# GICSS0_GIC register map
Vendor: Texas Instruments
Peripheral module from a debugger description file (folder am62A).
Registers are 32-bit, access not given, no defined reset value unless marked. A register's access mark holds for its fields unless they carry their own. Offsets are as the file gives them; lines under a group give offsets from that group; [hi:lo] are bit positions; {n}, {i} and the like mark numbered series; 'fields as' and 'values as' point back to an identical list; <NAME> marks a mode.

## GICSS0_GIC
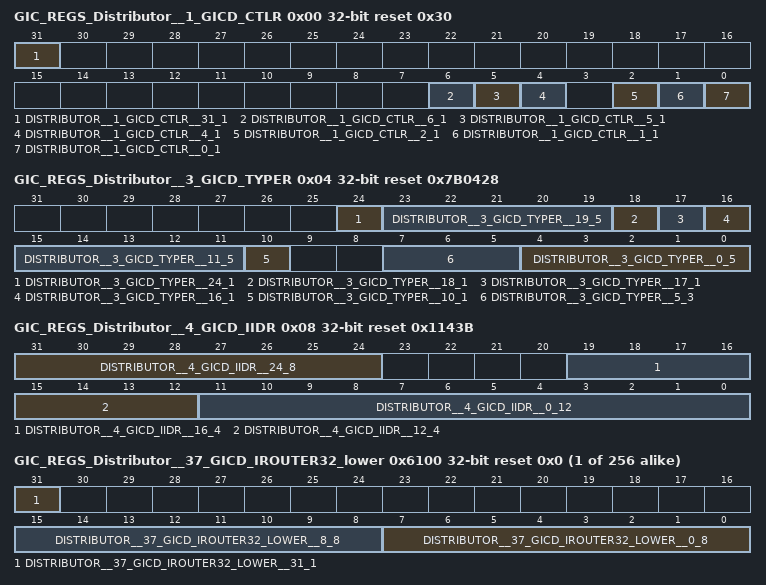
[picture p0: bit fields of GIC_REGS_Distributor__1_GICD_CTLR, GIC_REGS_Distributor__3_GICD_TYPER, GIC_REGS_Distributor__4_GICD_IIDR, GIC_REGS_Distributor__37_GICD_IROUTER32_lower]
0x00 GIC_REGS_Distributor__1_GICD_CTLR rw reset 0x30 — GICD_CTLR
  [31] DISTRIBUTOR__1_GICD_CTLR__31_1 — Register Write Pending
  [6] DISTRIBUTOR__1_GICD_CTLR__6_1 — S: DS
  [5] DISTRIBUTOR__1_GICD_CTLR__5_1 — S: ARE_NS
  [4] DISTRIBUTOR__1_GICD_CTLR__4_1 — NS: ARE_NS S: ARE_S
  [2] DISTRIBUTOR__1_GICD_CTLR__2_1 — S: EnableGrp1_S
  [1] DISTRIBUTOR__1_GICD_CTLR__1_1 — NS: EnableGrp1A S: EnableGrp1_NS
  [0] DISTRIBUTOR__1_GICD_CTLR__0_1 — NS: EnableGrp1 S: EnableGrp0
0x04 GIC_REGS_Distributor__3_GICD_TYPER rw reset 0x7B0428 — GICD_TYPER
  [24] DISTRIBUTOR__3_GICD_TYPER__24_1 — A3V
  [23:19] DISTRIBUTOR__3_GICD_TYPER__19_5 — IDbits
  [18] DISTRIBUTOR__3_GICD_TYPER__18_1 — DVIS
  [17] DISTRIBUTOR__3_GICD_TYPER__17_1 — LPIS
  [16] DISTRIBUTOR__3_GICD_TYPER__16_1 — MBIS
  [15:11] DISTRIBUTOR__3_GICD_TYPER__11_5 — LSPI
  [10] DISTRIBUTOR__3_GICD_TYPER__10_1 — SecurityExtn
  [7:5] DISTRIBUTOR__3_GICD_TYPER__5_3 — CPUNumber
  [4:0] DISTRIBUTOR__3_GICD_TYPER__0_5 — ITLinesNumber
0x08 GIC_REGS_Distributor__4_GICD_IIDR rw reset 0x1143B — GICD_IIDR
  [31:24] DISTRIBUTOR__4_GICD_IIDR__24_8 — ProductID
  [19:16] DISTRIBUTOR__4_GICD_IIDR__16_4 — Variant
  [15:12] DISTRIBUTOR__4_GICD_IIDR__12_4 — Revision
  [11:0] DISTRIBUTOR__4_GICD_IIDR__0_12 — Implementer
0x40 GIC_REGS_Distributor__5_GICD_SETSPI_NSR rw reset 0x0 — GICD_SETSPI_NSR
  [9:0] DISTRIBUTOR__5_GICD_SETSPI_NSR__0_10 — SPI ID
0x48 GIC_REGS_Distributor__6_GICD_CLRSPI_NSR rw reset 0x0 — GICD_CLRSPI_NSR
  [9:0] DISTRIBUTOR__6_GICD_CLRSPI_NSR__0_10 — SPI ID
0x50 GIC_REGS_Distributor__7_GICD_SETSPI_SR rw reset 0x0 — GICD_SETSPI_SR
  [9:0] DISTRIBUTOR__7_GICD_SETSPI_SR__0_10 — SPI ID
0x58 GIC_REGS_Distributor__8_GICD_CLRSPI_SR rw reset 0x0 — GICD_CLRSPI_SR
  [9:0] DISTRIBUTOR__8_GICD_CLRSPI_SR__0_10 — SPI ID
0x80 GIC_REGS_Distributor__9_GICD_IGROUPR0 — GICD_IGROUPR0
{0x80+4i} GIC_REGS_Distributor__10_GICD_IGROUPR{i} (i=1..8) — GICD_IGROUPR{i}
{0x100+4i} GIC_REGS_Distributor__12_GICD_ISENABLER{i} (i=1..8) — GICD_ISENABLER{i}
{0x180+4i} GIC_REGS_Distributor__14_GICD_ICENABLER{i} (i=1..8) — GICD_ICENABLER{i}
{0x200+4i} GIC_REGS_Distributor__16_GICD_ISPENDR{i} (i=1..8) — GICD_ISPENDR{i}
{0x280+4i} GIC_REGS_Distributor__18_GICD_ICPENDR{i} (i=1..8) — GICD_ICPENDR{i}
{0x300+4i} GIC_REGS_Distributor__20_GICD_ISACTIVER{i} (i=1..8) — GICD_ISACTIVER{i}
{0x380+4i} GIC_REGS_Distributor__22_GICD_ICACTIVER{i} (i=1..8) — GICD_ICACTIVER{i}
{0x400+4i} GIC_REGS_Distributor__24_GICD_IPRIORITYR{i} (i=8..71) — GICD_IPRIORITYR{i}
{0x800+4i} GIC_REGS_Distributor__26_GICD_ITARGETSR{i} (i=8..71) — GICD_ITARGETSR{i}
{0xC00+4i} GIC_REGS_Distributor__29_GICD_ICFGR{i} (i=2..17) — GICD_ICFGR{i}
0xD00 GIC_REGS_Distributor__30_GICD_IGRPMODR0 — GICD_IGRPMODR0
{0xD00+4i} GIC_REGS_Distributor__31_GICD_IGRPMODR{i} (i=1..8) — GICD_IGRPMODR{i}
0xE00 GIC_REGS_Distributor__32_GICD_NSACR0 — GICD_NSACR0
0xE04 GIC_REGS_Distributor__32_GICD_NSACR1 — GICD_NSACR1
{0xE00+4i} GIC_REGS_Distributor__33_GICD_NSACR{i} (i=2..17) — GICD_NSACR{i}
{0x6000+8i} GIC_REGS_Distributor__37_GICD_IROUTER{i}_lower rw reset 0x0 (i=32..287) — GICD_IROUTER{i}_lower
  [31] DISTRIBUTOR__37_GICD_IROUTER{i}_LOWER__31_1 — IRM
  [15:8] DISTRIBUTOR__37_GICD_IROUTER{i}_LOWER__8_8 — A1
  [7:0] DISTRIBUTOR__37_GICD_IROUTER{i}_LOWER__0_8 — A0
{0x6004+8i} GIC_REGS_Distributor__37_GICD_IROUTER{i}_upper (i=32..287) — GICD_IROUTER{i}_upper
0xC000 GIC_REGS_Distributor__38_GICD_ESTATUSR rw reset 0x0 — GICD_ESTATUSR
  [31] DISTRIBUTOR__38_GICD_ESTATUSR__31_1 — SWRP
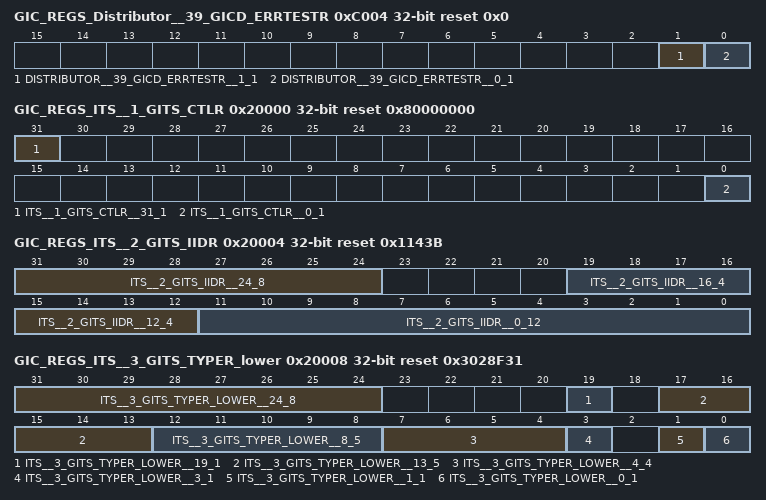
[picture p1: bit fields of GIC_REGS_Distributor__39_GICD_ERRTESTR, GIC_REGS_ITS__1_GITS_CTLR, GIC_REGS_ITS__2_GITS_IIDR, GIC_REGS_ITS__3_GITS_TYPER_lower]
0xC004 GIC_REGS_Distributor__39_GICD_ERRTESTR rw reset 0x0 — GICD_ERRTESTR
  [1] DISTRIBUTOR__39_GICD_ERRTESTR__1_1 — AXIM_err
  [0] DISTRIBUTOR__39_GICD_ERRTESTR__0_1 — ECC_fatal
{0xC084+4i} GIC_REGS_Distributor__40_GICD_SPISR{i} (i=0..7) — GICD_SPISR{i}
{0xFF2C+4i} GIC_REGS_Distributor__{i}_GICD_PIDR{i-37} (i=41..44) — GICD_PIDR{i-37}
{0xFF2C+4i} GIC_REGS_Distributor__{i}_GICD_PIDR{i-45} (i=45..48) — GICD_PIDR{i-45}
{0xFF2C+4i} GIC_REGS_Distributor__{i}_GICD_CIDR{i-49} (i=49..52) — GICD_CIDR{i-49}
0x10040 GIC_REGS_Message_based_SPIs__1_GICD_SETSPI_NSR rw reset 0x0 — GICD_SETSPI_NSR
  [9:0] MESSAGE_BASED_SPIS__1_GICD_SETSPI_NSR__0_10 — SPI ID
0x10048 GIC_REGS_Message_based_SPIs__2_GICD_CLRSPI_NSR rw reset 0x0 — GICD_CLRSPI_NSR
  [9:0] MESSAGE_BASED_SPIS__2_GICD_CLRSPI_NSR__0_10 — SPI ID
0x10050 GIC_REGS_Message_based_SPIs__3_GICD_SETSPI_SR rw reset 0x0 — GICD_SETSPI_SR
  [9:0] MESSAGE_BASED_SPIS__3_GICD_SETSPI_SR__0_10 — SPI ID
0x10058 GIC_REGS_Message_based_SPIs__4_GICD_CLRSPI_SR rw reset 0x0 — GICD_CLRSPI_SR
  [9:0] MESSAGE_BASED_SPIS__4_GICD_CLRSPI_SR__0_10 — SPI ID
0x20000 GIC_REGS_ITS__1_GITS_CTLR rw reset 0x80000000 — GITS_CTLR
  [31] ITS__1_GITS_CTLR__31_1 — Quiescent
  [0] ITS__1_GITS_CTLR__0_1 — Enabled
0x20004 GIC_REGS_ITS__2_GITS_IIDR rw reset 0x1143B — GITS_IIDR
  [31:24] ITS__2_GITS_IIDR__24_8 — ProductID
  [19:16] ITS__2_GITS_IIDR__16_4 — Variant
  [15:12] ITS__2_GITS_IIDR__12_4 — Revision
  [11:0] ITS__2_GITS_IIDR__0_12 — Implementer
0x20008 GIC_REGS_ITS__3_GITS_TYPER_lower rw reset 0x3028F31 — GITS_TYPER_lower
  [31:24] ITS__3_GITS_TYPER_LOWER__24_8 — HCC
  [19] ITS__3_GITS_TYPER_LOWER__19_1 — PTA
  [17:13] ITS__3_GITS_TYPER_LOWER__13_5 — Devbits
  [12:8] ITS__3_GITS_TYPER_LOWER__8_5 — IDbits
  [7:4] ITS__3_GITS_TYPER_LOWER__4_4 — ITT Entry Size
  [3] ITS__3_GITS_TYPER_LOWER__3_1 — Distributed
  [1] ITS__3_GITS_TYPER_LOWER__1_1 — VLPIS
  [0] ITS__3_GITS_TYPER_LOWER__0_1 — PLPIS
0x2000C GIC_REGS_ITS__4_GITS_TYPER_upper — GITS_TYPER_upper
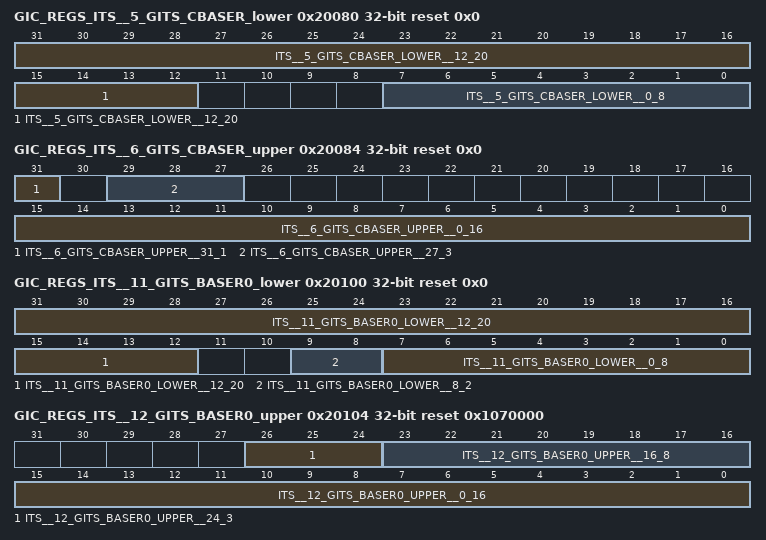
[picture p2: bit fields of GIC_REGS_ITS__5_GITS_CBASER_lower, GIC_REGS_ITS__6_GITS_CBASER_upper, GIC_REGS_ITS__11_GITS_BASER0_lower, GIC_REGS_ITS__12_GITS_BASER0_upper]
0x20080 GIC_REGS_ITS__5_GITS_CBASER_lower rw reset 0x0 — GITS_CBASER_lower
  [31:12] ITS__5_GITS_CBASER_LOWER__12_20 — Physical Address [31:12]
  [7:0] ITS__5_GITS_CBASER_LOWER__0_8 — Size
0x20084 GIC_REGS_ITS__6_GITS_CBASER_upper rw reset 0x0 — GITS_CBASER_upper
  [31] ITS__6_GITS_CBASER_UPPER__31_1 — Valid
  [29:27] ITS__6_GITS_CBASER_UPPER__27_3 — Cacheability
  [15:0] ITS__6_GITS_CBASER_UPPER__0_16 — Physical Address [47:32]
0x20088 GIC_REGS_ITS__7_GITS_CWRITER_lower rw reset 0x0 — GITS_CWRITER_lower
  [19:5] ITS__7_GITS_CWRITER_LOWER__5_15 — Offset
0x2008C GIC_REGS_ITS__8_GITS_CWRITER_upper — GITS_CWRITER_upper
0x20090 GIC_REGS_ITS__9_GITS_CREADR_lower rw reset 0x0 — GITS_CREADR_lower
  [19:5] ITS__9_GITS_CREADR_LOWER__5_15 — Offset
0x20094 GIC_REGS_ITS__10_GITS_CREADR_upper — GITS_CREADR_upper
0x20100 GIC_REGS_ITS__11_GITS_BASER0_lower rw reset 0x0 — GITS_BASER0_lower
  [31:12] ITS__11_GITS_BASER0_LOWER__12_20 — Physical Address [31:12]
  [9:8] ITS__11_GITS_BASER0_LOWER__8_2 — Page Size
  [7:0] ITS__11_GITS_BASER0_LOWER__0_8 — Size
0x20104 GIC_REGS_ITS__12_GITS_BASER0_upper rw reset 0x1070000 — GITS_BASER0_upper
  [26:24] ITS__12_GITS_BASER0_UPPER__24_3 — Type
  [23:16] ITS__12_GITS_BASER0_UPPER__16_8 — Entry Size
  [15:0] ITS__12_GITS_BASER0_UPPER__0_16 — Physical Address [47:32]
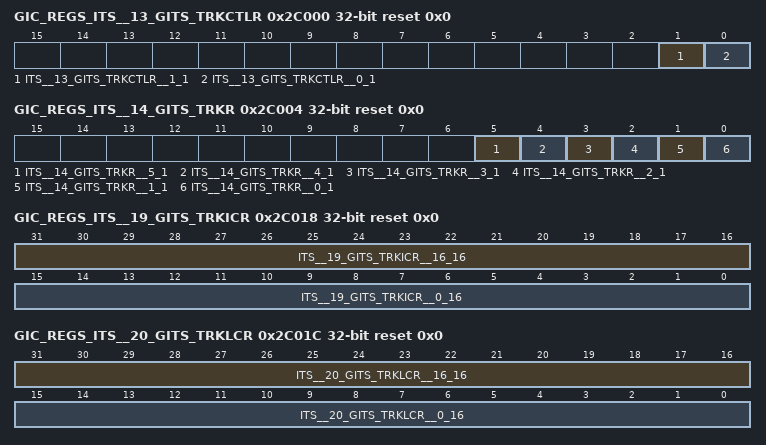
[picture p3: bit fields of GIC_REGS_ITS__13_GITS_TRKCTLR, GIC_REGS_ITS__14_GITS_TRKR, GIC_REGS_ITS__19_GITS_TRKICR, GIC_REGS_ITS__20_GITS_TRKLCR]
0x2C000 GIC_REGS_ITS__13_GITS_TRKCTLR rw reset 0x0 — GITS_TRKCTLR
  [1] ITS__13_GITS_TRKCTLR__1_1 — ITS track
  [0] ITS__13_GITS_TRKCTLR__0_1 — Cache count reset
0x2C004 GIC_REGS_ITS__14_GITS_TRKR rw reset 0x0 — GITS_TRKR
  [5] ITS__14_GITS_TRKR__5_1 — Translated ID out of range
  [4] ITS__14_GITS_TRKR__4_1 — Target CPU out of range
  [3] ITS__14_GITS_TRKR__3_1 — DID/ID not mapped
  [2] ITS__14_GITS_TRKR__2_1 — Input ID out of range
  [1] ITS__14_GITS_TRKR__1_1 — DID unmapped
  [0] ITS__14_GITS_TRKR__0_1 — DID out of range
0x2C008 GIC_REGS_ITS__15_GITS_TRKDIDR rw reset 0x0 — GITS_TRKDIDR
  [19:0] ITS__15_GITS_TRKDIDR__0_20 — DID
0x2C00C GIC_REGS_ITS__16_GITS_TRKPIDR rw reset 0x0 — GITS_TRKPIDR
  [15:0] ITS__16_GITS_TRKPIDR__0_16 — Translated ID
0x2C010 GIC_REGS_ITS__17_GITS_TRKVIDR rw reset 0x0 — GITS_TRKVIDR
  [15:0] ITS__17_GITS_TRKVIDR__0_16 — Input ID
0x2C014 GIC_REGS_ITS__18_GITS_TRKTGTR rw reset 0x0 — GITS_TRKTGTR
  [6:0] ITS__18_GITS_TRKTGTR__0_7 — Target CPU
0x2C018 GIC_REGS_ITS__19_GITS_TRKICR rw reset 0x0 — GITS_TRKICR
  [31:16] ITS__19_GITS_TRKICR__16_16 — ITE cache hits
  [15:0] ITS__19_GITS_TRKICR__0_16 — ITE cache misses
0x2C01C GIC_REGS_ITS__20_GITS_TRKLCR rw reset 0x0 — GITS_TRKLCR
  [31:16] ITS__20_GITS_TRKLCR__16_16 — LPI cache hits
  [15:0] ITS__20_GITS_TRKLCR__0_16 — LPI cache misses
{0x2FF7C+4i} GIC_REGS_ITS__{i}_GITS_PIDR{i-17} (i=21..24) — GITS_PIDR{i-17}
{0x2FF7C+4i} GIC_REGS_ITS__{i}_GITS_PIDR{i-25} (i=25..28) — GITS_PIDR{i-25}
{0x2FF7C+4i} GIC_REGS_ITS__{i}_GITS_CIDR{i-29} (i=29..32) — GITS_CIDR{i-29}
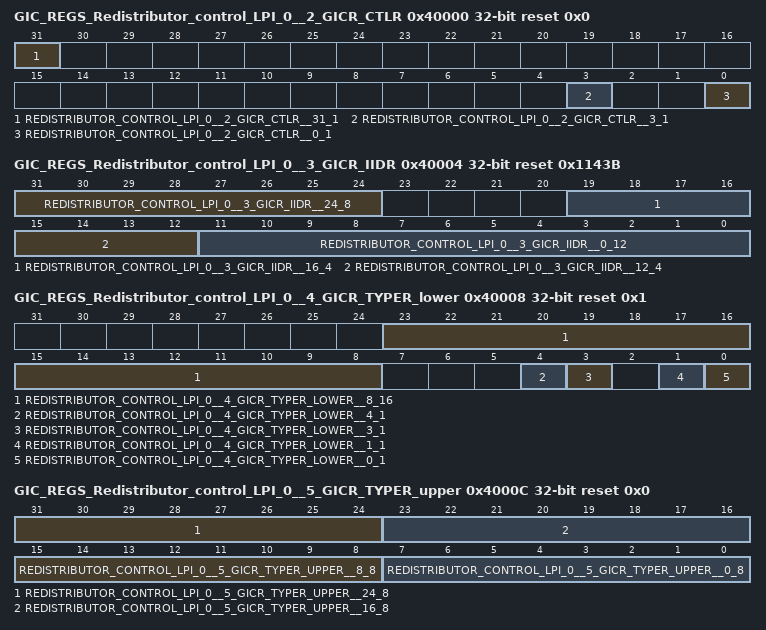
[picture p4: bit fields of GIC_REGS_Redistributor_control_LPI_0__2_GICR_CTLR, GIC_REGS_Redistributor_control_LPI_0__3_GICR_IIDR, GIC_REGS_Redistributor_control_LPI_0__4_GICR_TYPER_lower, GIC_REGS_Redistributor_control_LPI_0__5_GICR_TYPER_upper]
0x40000 GIC_REGS_Redistributor_control_LPI_0__2_GICR_CTLR rw reset 0x0 — GICR_CTLR
  [31] REDISTRIBUTOR_CONTROL_LPI_0__2_GICR_CTLR__31_1 — Upstream Write Pending
  [3] REDISTRIBUTOR_CONTROL_LPI_0__2_GICR_CTLR__3_1 — Register Write Pending
  [0] REDISTRIBUTOR_CONTROL_LPI_0__2_GICR_CTLR__0_1 — Enable LPIs
0x40004 GIC_REGS_Redistributor_control_LPI_0__3_GICR_IIDR rw reset 0x1143B — GICR_IIDR
  [31:24] REDISTRIBUTOR_CONTROL_LPI_0__3_GICR_IIDR__24_8 — ProductID
  [19:16] REDISTRIBUTOR_CONTROL_LPI_0__3_GICR_IIDR__16_4 — Variant
  [15:12] REDISTRIBUTOR_CONTROL_LPI_0__3_GICR_IIDR__12_4 — Revision
  [11:0] REDISTRIBUTOR_CONTROL_LPI_0__3_GICR_IIDR__0_12 — Implementer
0x40008 GIC_REGS_Redistributor_control_LPI_0__4_GICR_TYPER_lower rw reset 0x1 — GICR_TYPER_lower
  [23:8] REDISTRIBUTOR_CONTROL_LPI_0__4_GICR_TYPER_LOWER__8_16 — Processor Number
  [4] REDISTRIBUTOR_CONTROL_LPI_0__4_GICR_TYPER_LOWER__4_1 — Last
  [3] REDISTRIBUTOR_CONTROL_LPI_0__4_GICR_TYPER_LOWER__3_1 — Distributed
  [1] REDISTRIBUTOR_CONTROL_LPI_0__4_GICR_TYPER_LOWER__1_1 — VLPIS
  [0] REDISTRIBUTOR_CONTROL_LPI_0__4_GICR_TYPER_LOWER__0_1 — PLPIS
0x4000C GIC_REGS_Redistributor_control_LPI_0__5_GICR_TYPER_upper rw reset 0x0 — GICR_TYPER_upper
  [31:24] REDISTRIBUTOR_CONTROL_LPI_0__5_GICR_TYPER_UPPER__24_8 — A3
  [23:16] REDISTRIBUTOR_CONTROL_LPI_0__5_GICR_TYPER_UPPER__16_8 — A2
  [15:8] REDISTRIBUTOR_CONTROL_LPI_0__5_GICR_TYPER_UPPER__8_8 — A1
  [7:0] REDISTRIBUTOR_CONTROL_LPI_0__5_GICR_TYPER_UPPER__0_8 — A0
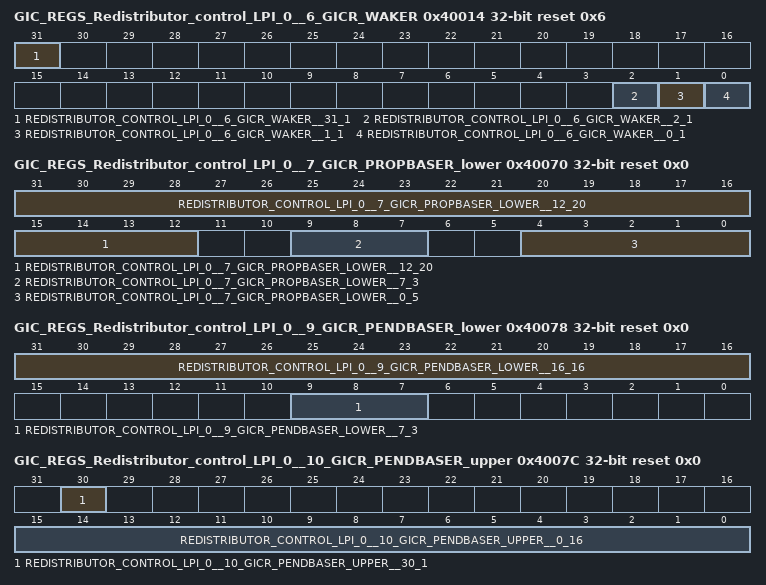
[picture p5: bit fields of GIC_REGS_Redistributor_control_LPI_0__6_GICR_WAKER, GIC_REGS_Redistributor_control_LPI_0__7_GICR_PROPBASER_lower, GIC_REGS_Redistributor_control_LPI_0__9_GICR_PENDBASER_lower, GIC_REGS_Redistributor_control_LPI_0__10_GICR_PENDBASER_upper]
0x40014 GIC_REGS_Redistributor_control_LPI_0__6_GICR_WAKER rw reset 0x6 — GICR_WAKER
  [31] REDISTRIBUTOR_CONTROL_LPI_0__6_GICR_WAKER__31_1 — Quiescent
  [2] REDISTRIBUTOR_CONTROL_LPI_0__6_GICR_WAKER__2_1 — ChildrenAsleep
  [1] REDISTRIBUTOR_CONTROL_LPI_0__6_GICR_WAKER__1_1 — ProcessorSleep
  [0] REDISTRIBUTOR_CONTROL_LPI_0__6_GICR_WAKER__0_1 — Sleep
0x40070 GIC_REGS_Redistributor_control_LPI_0__7_GICR_PROPBASER_lower rw reset 0x0 — GICR_PROPBASER_lower
  [31:12] REDISTRIBUTOR_CONTROL_LPI_0__7_GICR_PROPBASER_LOWER__12_20 — Physical Address [31:12]
  [9:7] REDISTRIBUTOR_CONTROL_LPI_0__7_GICR_PROPBASER_LOWER__7_3 — Cacheability
  [4:0] REDISTRIBUTOR_CONTROL_LPI_0__7_GICR_PROPBASER_LOWER__0_5 — Idbits
0x40074 GIC_REGS_Redistributor_control_LPI_0__8_GICR_PROPBASER_upper rw reset 0x0 — GICR_PROPBASER_upper
  [15:0] REDISTRIBUTOR_CONTROL_LPI_0__8_GICR_PROPBASER_UPPER__0_16 — Physical Address [47:32]
0x40078 GIC_REGS_Redistributor_control_LPI_0__9_GICR_PENDBASER_lower rw reset 0x0 — GICR_PENDBASER_lower
  [31:16] REDISTRIBUTOR_CONTROL_LPI_0__9_GICR_PENDBASER_LOWER__16_16 — Physical Address [31:16]
  [9:7] REDISTRIBUTOR_CONTROL_LPI_0__9_GICR_PENDBASER_LOWER__7_3 — Cacheability
0x4007C GIC_REGS_Redistributor_control_LPI_0__10_GICR_PENDBASER_upper rw reset 0x0 — GICR_PENDBASER_upper
  [30] REDISTRIBUTOR_CONTROL_LPI_0__10_GICR_PENDBASER_UPPER__30_1 — Pending Table Zero
  [15:0] REDISTRIBUTOR_CONTROL_LPI_0__10_GICR_PENDBASER_UPPER__0_16 — Physical Address [47:32]
0x4FFD0 GIC_REGS_Redistributor_control_LPI_0__11_GICR_PIDR4 — GICR_PIDR4
0x4FFD4 GIC_REGS_Redistributor_control_LPI_0__12_GICR_PIDR5 — GICR_PIDR5
0x4FFD8 GIC_REGS_Redistributor_control_LPI_0__13_GICR_PIDR6 — GICR_PIDR6
0x4FFDC GIC_REGS_Redistributor_control_LPI_0__14_GICR_PIDR7 — GICR_PIDR7
0x4FFE0 GIC_REGS_Redistributor_control_LPI_0__15_GICR_PIDR0 — GICR_PIDR0
0x4FFE4 GIC_REGS_Redistributor_control_LPI_0__16_GICR_PIDR1 — GICR_PIDR1
0x4FFE8 GIC_REGS_Redistributor_control_LPI_0__17_GICR_PIDR2 — GICR_PIDR2
0x4FFEC GIC_REGS_Redistributor_control_LPI_0__18_GICR_PIDR3 — GICR_PIDR3
0x4FFF0 GIC_REGS_Redistributor_control_LPI_0__19_GICR_CIDR0 — GICR_CIDR0
0x4FFF4 GIC_REGS_Redistributor_control_LPI_0__20_GICR_CIDR1 — GICR_CIDR1
0x4FFF8 GIC_REGS_Redistributor_control_LPI_0__21_GICR_CIDR2 — GICR_CIDR2
0x4FFFC GIC_REGS_Redistributor_control_LPI_0__22_GICR_CIDR3 — GICR_CIDR3
0x50080 GIC_REGS_Redistributor_SGI_PPI_0__1_GICR_IGROUPR0 — GICR_IGROUPR0
0x50100 GIC_REGS_Redistributor_SGI_PPI_0__2_GICR_ISENABLER0 — GICR_ISENABLER0
0x50180 GIC_REGS_Redistributor_SGI_PPI_0__3_GICR_ICENABLER0 — GICR_ICENABLER0
0x50200 GIC_REGS_Redistributor_SGI_PPI_0__4_GICR_ISPENDR0 — GICR_ISPENDR0
0x50280 GIC_REGS_Redistributor_SGI_PPI_0__5_GICR_ICPENDR0 — GICR_ICPENDR0
0x50300 GIC_REGS_Redistributor_SGI_PPI_0__6_GICR_ISACTIVER0 — GICR_ISACTIVER0
0x50380 GIC_REGS_Redistributor_SGI_PPI_0__7_GICR_ICACTIVER0 — GICR_ICACTIVER0
{0x50400+4i} GIC_REGS_Redistributor_SGI_PPI_0__8_GICR_IPRIORITYR{i} (i=0..7) — GICR_IPRIORITYR{i}
0x50C00 GIC_REGS_Redistributor_SGI_PPI_0__9_GICR_ICFGR0 — GICR_ICFGR0
0x50C04 GIC_REGS_Redistributor_SGI_PPI_0__10_GICR_ICFGR1 — GICR_ICFGR1
0x50D00 GIC_REGS_Redistributor_SGI_PPI_0__11_GICR_IGRPMODR0 — GICR_IGRPMODR0
0x50E00 GIC_REGS_Redistributor_SGI_PPI_0__12_GICR_NSACR — GICR_NSACR
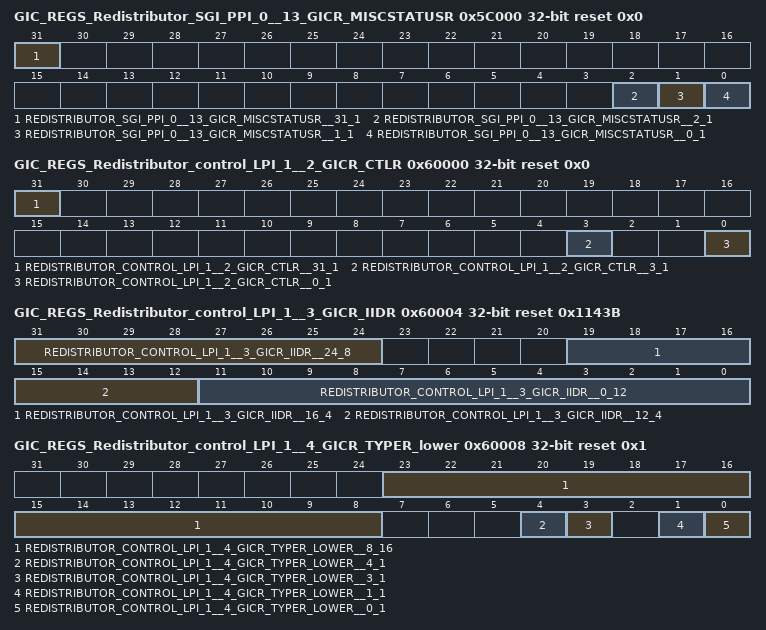
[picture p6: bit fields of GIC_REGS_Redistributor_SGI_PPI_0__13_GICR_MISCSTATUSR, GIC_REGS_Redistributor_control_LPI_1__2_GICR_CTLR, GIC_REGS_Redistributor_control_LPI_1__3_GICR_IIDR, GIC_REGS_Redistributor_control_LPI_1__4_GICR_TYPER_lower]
0x5C000 GIC_REGS_Redistributor_SGI_PPI_0__13_GICR_MISCSTATUSR rw reset 0x0 — GICR_MISCSTATUSR
  [31] REDISTRIBUTOR_SGI_PPI_0__13_GICR_MISCSTATUSR__31_1 — cpu_active
  [2] REDISTRIBUTOR_SGI_PPI_0__13_GICR_MISCSTATUSR__2_1 — EnableGrp1_S
  [1] REDISTRIBUTOR_SGI_PPI_0__13_GICR_MISCSTATUSR__1_1 — EnableGrp1_NS
  [0] REDISTRIBUTOR_SGI_PPI_0__13_GICR_MISCSTATUSR__0_1 — EnableGrp0
0x5C080 GIC_REGS_Redistributor_SGI_PPI_0__14_GICR_PPISR rw reset 0x0 — GICR_PPISR
  [31:16] REDISTRIBUTOR_SGI_PPI_0__14_GICR_PPISR__16_16 — PPI status
0x60000 GIC_REGS_Redistributor_control_LPI_1__2_GICR_CTLR rw reset 0x0 — GICR_CTLR
  [31] REDISTRIBUTOR_CONTROL_LPI_1__2_GICR_CTLR__31_1 — Upstream Write Pending
  [3] REDISTRIBUTOR_CONTROL_LPI_1__2_GICR_CTLR__3_1 — Register Write Pending
  [0] REDISTRIBUTOR_CONTROL_LPI_1__2_GICR_CTLR__0_1 — Enable LPIs
0x60004 GIC_REGS_Redistributor_control_LPI_1__3_GICR_IIDR rw reset 0x1143B — GICR_IIDR
  [31:24] REDISTRIBUTOR_CONTROL_LPI_1__3_GICR_IIDR__24_8 — ProductID
  [19:16] REDISTRIBUTOR_CONTROL_LPI_1__3_GICR_IIDR__16_4 — Variant
  [15:12] REDISTRIBUTOR_CONTROL_LPI_1__3_GICR_IIDR__12_4 — Revision
  [11:0] REDISTRIBUTOR_CONTROL_LPI_1__3_GICR_IIDR__0_12 — Implementer
0x60008 GIC_REGS_Redistributor_control_LPI_1__4_GICR_TYPER_lower rw reset 0x1 — GICR_TYPER_lower
  [23:8] REDISTRIBUTOR_CONTROL_LPI_1__4_GICR_TYPER_LOWER__8_16 — Processor Number
  [4] REDISTRIBUTOR_CONTROL_LPI_1__4_GICR_TYPER_LOWER__4_1 — Last
  [3] REDISTRIBUTOR_CONTROL_LPI_1__4_GICR_TYPER_LOWER__3_1 — Distributed
  [1] REDISTRIBUTOR_CONTROL_LPI_1__4_GICR_TYPER_LOWER__1_1 — VLPIS
  [0] REDISTRIBUTOR_CONTROL_LPI_1__4_GICR_TYPER_LOWER__0_1 — PLPIS
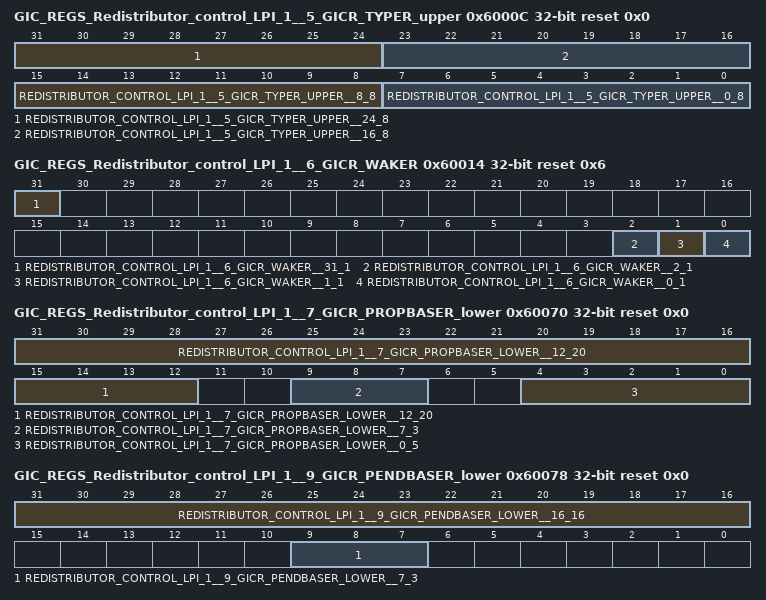
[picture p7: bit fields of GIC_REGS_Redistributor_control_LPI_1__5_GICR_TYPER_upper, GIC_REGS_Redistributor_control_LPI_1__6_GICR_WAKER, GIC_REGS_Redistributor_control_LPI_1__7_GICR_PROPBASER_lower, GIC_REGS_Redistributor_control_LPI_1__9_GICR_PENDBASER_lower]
0x6000C GIC_REGS_Redistributor_control_LPI_1__5_GICR_TYPER_upper rw reset 0x0 — GICR_TYPER_upper
  [31:24] REDISTRIBUTOR_CONTROL_LPI_1__5_GICR_TYPER_UPPER__24_8 — A3
  [23:16] REDISTRIBUTOR_CONTROL_LPI_1__5_GICR_TYPER_UPPER__16_8 — A2
  [15:8] REDISTRIBUTOR_CONTROL_LPI_1__5_GICR_TYPER_UPPER__8_8 — A1
  [7:0] REDISTRIBUTOR_CONTROL_LPI_1__5_GICR_TYPER_UPPER__0_8 — A0
0x60014 GIC_REGS_Redistributor_control_LPI_1__6_GICR_WAKER rw reset 0x6 — GICR_WAKER
  [31] REDISTRIBUTOR_CONTROL_LPI_1__6_GICR_WAKER__31_1 — Quiescent
  [2] REDISTRIBUTOR_CONTROL_LPI_1__6_GICR_WAKER__2_1 — ChildrenAsleep
  [1] REDISTRIBUTOR_CONTROL_LPI_1__6_GICR_WAKER__1_1 — ProcessorSleep
  [0] REDISTRIBUTOR_CONTROL_LPI_1__6_GICR_WAKER__0_1 — Sleep
0x60070 GIC_REGS_Redistributor_control_LPI_1__7_GICR_PROPBASER_lower rw reset 0x0 — GICR_PROPBASER_lower
  [31:12] REDISTRIBUTOR_CONTROL_LPI_1__7_GICR_PROPBASER_LOWER__12_20 — Physical Address [31:12]
  [9:7] REDISTRIBUTOR_CONTROL_LPI_1__7_GICR_PROPBASER_LOWER__7_3 — Cacheability
  [4:0] REDISTRIBUTOR_CONTROL_LPI_1__7_GICR_PROPBASER_LOWER__0_5 — Idbits
0x60074 GIC_REGS_Redistributor_control_LPI_1__8_GICR_PROPBASER_upper rw reset 0x0 — GICR_PROPBASER_upper
  [15:0] REDISTRIBUTOR_CONTROL_LPI_1__8_GICR_PROPBASER_UPPER__0_16 — Physical Address [47:32]
0x60078 GIC_REGS_Redistributor_control_LPI_1__9_GICR_PENDBASER_lower rw reset 0x0 — GICR_PENDBASER_lower
  [31:16] REDISTRIBUTOR_CONTROL_LPI_1__9_GICR_PENDBASER_LOWER__16_16 — Physical Address [31:16]
  [9:7] REDISTRIBUTOR_CONTROL_LPI_1__9_GICR_PENDBASER_LOWER__7_3 — Cacheability
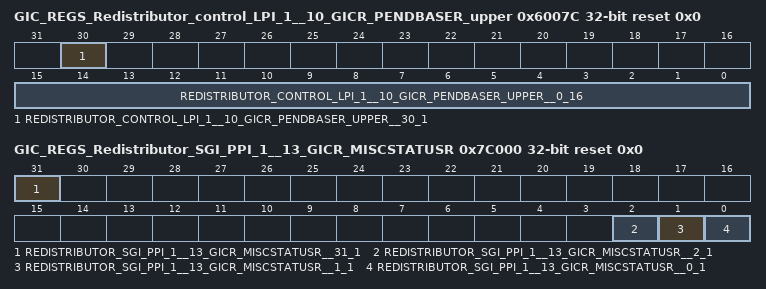
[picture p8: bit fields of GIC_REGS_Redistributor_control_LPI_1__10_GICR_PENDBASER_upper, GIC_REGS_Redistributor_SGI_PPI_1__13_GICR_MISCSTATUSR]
0x6007C GIC_REGS_Redistributor_control_LPI_1__10_GICR_PENDBASER_upper rw reset 0x0 — GICR_PENDBASER_upper
  [30] REDISTRIBUTOR_CONTROL_LPI_1__10_GICR_PENDBASER_UPPER__30_1 — Pending Table Zero
  [15:0] REDISTRIBUTOR_CONTROL_LPI_1__10_GICR_PENDBASER_UPPER__0_16 — Physical Address [47:32]
0x6FFD0 GIC_REGS_Redistributor_control_LPI_1__11_GICR_PIDR4 — GICR_PIDR4
0x6FFD4 GIC_REGS_Redistributor_control_LPI_1__12_GICR_PIDR5 — GICR_PIDR5
0x6FFD8 GIC_REGS_Redistributor_control_LPI_1__13_GICR_PIDR6 — GICR_PIDR6
0x6FFDC GIC_REGS_Redistributor_control_LPI_1__14_GICR_PIDR7 — GICR_PIDR7
0x6FFE0 GIC_REGS_Redistributor_control_LPI_1__15_GICR_PIDR0 — GICR_PIDR0
0x6FFE4 GIC_REGS_Redistributor_control_LPI_1__16_GICR_PIDR1 — GICR_PIDR1
0x6FFE8 GIC_REGS_Redistributor_control_LPI_1__17_GICR_PIDR2 — GICR_PIDR2
0x6FFEC GIC_REGS_Redistributor_control_LPI_1__18_GICR_PIDR3 — GICR_PIDR3
0x6FFF0 GIC_REGS_Redistributor_control_LPI_1__19_GICR_CIDR0 — GICR_CIDR0
0x6FFF4 GIC_REGS_Redistributor_control_LPI_1__20_GICR_CIDR1 — GICR_CIDR1
0x6FFF8 GIC_REGS_Redistributor_control_LPI_1__21_GICR_CIDR2 — GICR_CIDR2
0x6FFFC GIC_REGS_Redistributor_control_LPI_1__22_GICR_CIDR3 — GICR_CIDR3
0x70080 GIC_REGS_Redistributor_SGI_PPI_1__1_GICR_IGROUPR0 — GICR_IGROUPR0
0x70100 GIC_REGS_Redistributor_SGI_PPI_1__2_GICR_ISENABLER0 — GICR_ISENABLER0
0x70180 GIC_REGS_Redistributor_SGI_PPI_1__3_GICR_ICENABLER0 — GICR_ICENABLER0
0x70200 GIC_REGS_Redistributor_SGI_PPI_1__4_GICR_ISPENDR0 — GICR_ISPENDR0
0x70280 GIC_REGS_Redistributor_SGI_PPI_1__5_GICR_ICPENDR0 — GICR_ICPENDR0
0x70300 GIC_REGS_Redistributor_SGI_PPI_1__6_GICR_ISACTIVER0 — GICR_ISACTIVER0
0x70380 GIC_REGS_Redistributor_SGI_PPI_1__7_GICR_ICACTIVER0 — GICR_ICACTIVER0
{0x70400+4i} GIC_REGS_Redistributor_SGI_PPI_1__8_GICR_IPRIORITYR{i} (i=0..7) — GICR_IPRIORITYR{i}
0x70C00 GIC_REGS_Redistributor_SGI_PPI_1__9_GICR_ICFGR0 — GICR_ICFGR0
0x70C04 GIC_REGS_Redistributor_SGI_PPI_1__10_GICR_ICFGR1 — GICR_ICFGR1
0x70D00 GIC_REGS_Redistributor_SGI_PPI_1__11_GICR_IGRPMODR0 — GICR_IGRPMODR0
0x70E00 GIC_REGS_Redistributor_SGI_PPI_1__12_GICR_NSACR — GICR_NSACR
0x7C000 GIC_REGS_Redistributor_SGI_PPI_1__13_GICR_MISCSTATUSR rw reset 0x0 — GICR_MISCSTATUSR
  [31] REDISTRIBUTOR_SGI_PPI_1__13_GICR_MISCSTATUSR__31_1 — cpu_active
  [2] REDISTRIBUTOR_SGI_PPI_1__13_GICR_MISCSTATUSR__2_1 — EnableGrp1_S
  [1] REDISTRIBUTOR_SGI_PPI_1__13_GICR_MISCSTATUSR__1_1 — EnableGrp1_NS
  [0] REDISTRIBUTOR_SGI_PPI_1__13_GICR_MISCSTATUSR__0_1 — EnableGrp0
0x7C080 GIC_REGS_Redistributor_SGI_PPI_1__14_GICR_PPISR rw reset 0x0 — GICR_PPISR
  [31:16] REDISTRIBUTOR_SGI_PPI_1__14_GICR_PPISR__16_16 — PPI status
